AUTOSAR XML (schema 4-2-2)
package /AUTOSAR_Dcm/SwComponentTypes
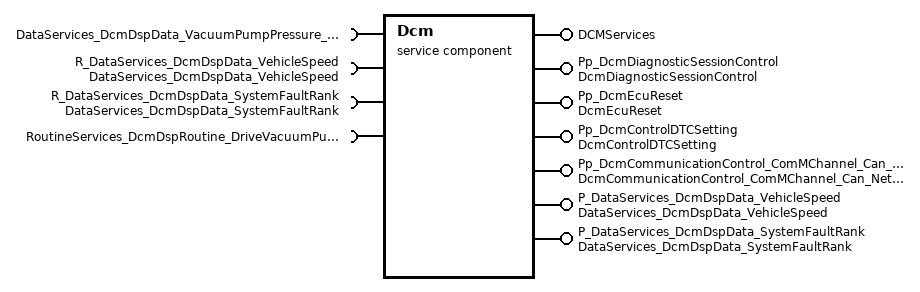
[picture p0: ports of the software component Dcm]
  service sw component type Dcm
    5 x provide port:
      DCMServices: provided-interface=DCMServices
      Pp_DcmDiagnosticSessionControl: mode-switch-sender-com-spec{mode-group=MDGP_DcmDiagnosticSessionControl, queue-length=1}, provided-interface=DcmDiagnosticSessionControl
      Pp_DcmEcuReset: mode-switch-sender-com-spec{mode-group=MDGP_DcmEcuReset, queue-length=1}, provided-interface=DcmEcuReset
      Pp_DcmControlDTCSetting: mode-switch-sender-com-spec{mode-group=MDGP_DcmControlDTCSetting, queue-length=1}, provided-interface=DcmControlDTCSetting
      Pp_DcmCommunicationControl_ComMChannel_Can_Network_Channel: mode-switch-sender-com-spec{mode-group=MDGP_DcmCommunicationControl_ComMChannel_Can_Network_Channel, queue-length=1}, provided-interface=DcmCommunicationControl_ComMChannel_Can_Network_Channel
    require port DataServices_DcmDspData_VacuumPumpPressure_1100: required-interface=DataServices_DcmDspData_VacuumPumpPressure_1100
    require port R_DataServices_DcmDspData_VehicleSpeed: required-interface=DataServices_DcmDspData_VehicleSpeed
    provide port P_DataServices_DcmDspData_VehicleSpeed: provided-interface=DataServices_DcmDspData_VehicleSpeed
    require port R_DataServices_DcmDspData_SystemFaultRank: required-interface=DataServices_DcmDspData_SystemFaultRank
    provide port P_DataServices_DcmDspData_SystemFaultRank: provided-interface=DataServices_DcmDspData_SystemFaultRank
    require port RoutineServices_DcmDspRoutine_DriveVacuumPump: required-interface=RoutineServices_DcmDspRoutine_DriveVacuumPump
    behavior IntBeh_Dcm: data-type-mapping=[DTS_DcmDiagnosticSessionControl, DTS_DcmEcuReset, DTS_DcmControlDTCSetting, DTS_DcmCommunicationControl_ComMChannel_Can_Network_Channel], included-data-type-set=data-type=[Dcm_SecLevelType, Dcm_SesCtrlType, Dcm_ProtocolType, Dcm_NegativeResponseCodeType, Dcm_ConfirmationStatusType, Dcm_OpStatusType, Dcm_DidSupportedType]
      5 x operation invoked event:
        OpInvEvent_DCMServices_GAP: start-on-event=Dcm_GetActiveProtocol, operation=DCMServices.GetActiveProtocol
        OpInvEvent_DCMServices_SAD: start-on-event=Dcm_SetActiveDiagnostic, operation=DCMServices.SetActiveDiagnostic
        OpInvEvent_DCMServices_GSCT: start-on-event=Dcm_GetSesCtrlType, operation=DCMServices.GetSesCtrlType
        OpInvEvent_DCMServices_GSL: start-on-event=Dcm_GetSecurityLevel, operation=DCMServices.GetSecurityLevel
        OpInvEvent_DCMServices_RD: start-on-event=Dcm_ResetToDefaultSession, operation=DCMServices.ResetToDefaultSession
      port-api-options:
        enable-take-address=true, indirect-api=false, port=DataServices_DcmDspData_VacuumPumpPressure_1100
        enable-take-address=true, indirect-api=false, port=RoutineServices_DcmDspRoutine_DriveVacuumPump
      6 x runnable:
        Dcm_MainFunction
          data-receive-point-by-arguments:
            access DcmDspData_VehicleSpeed_Read: accessed-variable=R_DataServices_DcmDspData_VehicleSpeed.Data
            access DcmDspData_SystemFaultRank_Read: accessed-variable=R_DataServices_DcmDspData_SystemFaultRank.Data
          data-send-points:
            access DcmDspData_VehicleSpeed_Write: accessed-variable=P_DataServices_DcmDspData_VehicleSpeed.Data
            access DcmDspData_SystemFaultRank_Write: accessed-variable=P_DataServices_DcmDspData_SystemFaultRank.Data
          4 x mode switch point:
            ModeSwitchPoint_0: mode-group=Pp_DcmDiagnosticSessionControl.MDGP_DcmDiagnosticSessionControl
            ModeSwitchPoint_1: mode-group=Pp_DcmEcuReset.MDGP_DcmEcuReset
            ModeSwitchPoint_3: mode-group=Pp_DcmControlDTCSetting.MDGP_DcmControlDTCSetting
            ModeSwitchPoint_ComMChannel_Can_Network_Channel: mode-group=Pp_DcmCommunicationControl_ComMChannel_Can_Network_Channel.MDGP_DcmCommunicationControl_ComMChannel_Can_Network_Channel
          8 x sync call, all with timeout=0.0:
            DataServices_DcmDspData_VacuumPumpPressure_1100_RData: operation=DataServices_DcmDspData_VacuumPumpPressure_1100.ReadData
            DataServices_DcmDspData_VacuumPumpPressure_1100_RCE: operation=DataServices_DcmDspData_VacuumPumpPressure_1100.ReturnControlToECU
            DataServices_DcmDspData_VacuumPumpPressure_1100_RD: operation=DataServices_DcmDspData_VacuumPumpPressure_1100.ResetToDefault
            DataServices_DcmDspData_VacuumPumpPressure_1100_STA: operation=DataServices_DcmDspData_VacuumPumpPressure_1100.ShortTermAdjustment
            DataServices_DcmDspData_VacuumPumpPressure_1100_FCS: operation=DataServices_DcmDspData_VacuumPumpPressure_1100.FreezeCurrentState
            SSC_Rout_DcmDspRoutine_DriveVacuumPump_Start: operation=RoutineServices_DcmDspRoutine_DriveVacuumPump.Start
            SSC_Rout_DcmDspRoutine_DriveVacuumPump_Stop: operation=RoutineServices_DcmDspRoutine_DriveVacuumPump.Stop
            SSC_Rout_DcmDspRoutine_DriveVacuumPump_ReqRes: operation=RoutineServices_DcmDspRoutine_DriveVacuumPump.RequestResults
        Dcm_GetActiveProtocol: can-be-invoked-concurrently=true
        Dcm_SetActiveDiagnostic: can-be-invoked-concurrently=true
        Dcm_GetSesCtrlType: can-be-invoked-concurrently=true
        Dcm_GetSecurityLevel: can-be-invoked-concurrently=true
        Dcm_ResetToDefaultSession: can-be-invoked-concurrently=true
package /AUTOSAR_Dcm/SwcImplementations
  swc implementation Impl_Dcm: programming-language=C, sw-version=42.5.0.0, swc-bsw-mapping=SwcBswMappings, vendor-id=6, behavior=IntBeh_Dcm
    code-descriptors:
      code CodeDescr_Dcm: artifact-descriptors=autosar-engineering-object={short-label=Code_0, category=SWSRC}
package /AUTOSAR_Dcm/CompuMethods
  compu method Dcm_RidSupportedType_Values: 0=DCM_RID_SUPPORTED_IN_RANGE, 1=DCM_RID_NOT_SUPPORTED
package /AUTOSAR_Dcm/ImplementationDataTypes
  21 x impl type:
    Dcm_SesCtrlType: compu {1=DCM_DEFAULT_SESSION, 2=DCM_PROGRAMMING_SESSION, 3=DCM_EXTENDED_DIAGNOSTIC_SESSION, 4=DCM_SAFETY_SYSTEM_DIAGNOSTIC_SESSION}, implementation-data-type=uint8
    Dcm_NegativeResponseCodeType: compu {17=DCM_E_SERVICENOTSUPPORTED, 18=DCM_E_SUBFUNCTIONNOTSUPPORTED, 19=DCM_E_INCORRECTMESSAGELENGTHORINVALIDFORMAT, 20=DCM_E_RESPONSETOOLONG, 53=DCM_E_INVALIDKEY, 54=DCM_E_EXCEEDNUMBEROFATTEMPTS, 55=DCM_E_REQUIREDTIMEDELAYNOTEXPIRED, 112=DCM_E_UPLOADDOWNLOADNOTACCEPTED, 113=DCM_E_TRANSFERDATASUSPENDED, 115=DCM_E_WRONGBLOCKSEQUENCECOUNTER, 127=DCM_E_SERVICENOTSUPPORTEDINACTIVESESSION, 140=DCM_E_TRANSMISSIONRANGENOTINNEUTRAL, 34=DCM_E_CONDITIONSNOTCORRECT, 16=DCM_E_GENERALREJECT, 33=DCM_E_BUSYREPEATREQUEST, 36=DCM_E_REQUESTSEQUENCEERROR, 37=DCM_E_NORESPONSEFROMSUBNETCOMPONENT, 38=DCM_E_FAILUREPREVENTSEXECUTIONOFREQUESTEDACTION, 49=DCM_E_REQUESTOUTOFRANGE, 51=DCM_E_SECURITYACCESSDENIED, 114=DCM_E_GENERALPROGRAMMINGFAILURE, 126=DCM_E_SUBFUNCTIONNOTSUPPORTEDINACTIVESESSION, 129=DCM_E_RPMTOOHIGH, 130=DCM_E_RPMTOOLOW, 131=DCM_E_ENGINEISRUNNING, 132=DCM_E_ENGINEISNOTRUNNING, 133=DCM_E_ENGINERUNTIMETOOLOW, 134=DCM_E_TEMPERATURETOOHIGH, 135=DCM_E_TEMPERATURETOOLOW, 136=DCM_E_VEHICLESPEEDTOOHIGH, 137=DCM_E_VEHICLESPEEDTOOLOW, 138=DCM_E_THROTTLE_PEDALTOOHIGH, 139=DCM_E_THROTTLE_PEDALTOOLOW, 141=DCM_E_TRANSMISSIONRANGENOTINGEAR, 146=DCM_E_VOLTAGETOOHIGH, 143=DCM_E_BRAKESWITCH_NOTCLOSED, 144=DCM_E_SHIFTERLEVERNOTINPARK, 145=DCM_E_TORQUECONVERTERCLUTCHLOCKED, 147=DCM_E_VOLTAGETOOLOW}, implementation-data-type=uint8
    Dcm_InputOutputControlParameterType: compu {255=DCM_IDLE, 3=DCM_SHORT_TERM_ADJUSTMENT, 2=DCM_FREEZE_CURRENT_STATE, 1=DCM_RESET_TO_DEFAULT, 0=DCM_RETURN_CONTROL_TO_ECU}, implementation-data-type=uint8
    Dcm_IOOperationResponseType: compu {255=DCM_IDLE, 0=DCM_POSITIVE_RESPONSE, 16=DCM_GENERAL_REJECT, 33=DCM_BUSY_REPEAT_REQUEST, 34=DCM_CONDITIONS_NOT_CORRECT, 38=DCM_FAILURE_PREVENTS_EXECUTION, 49=DCM_REQUEST_OUT_OF_RANGE, 120=DCM_RESPONSE_PENDING}, implementation-data-type=uint8
    Dcm_IOControlResponseType: category=STRUCTURE
      element IOOperationResponse: implementation-data-type=Dcm_IOOperationResponseType
    Dcm_DataArrayTypeUint8_DcmDspData_VacuumPumpPressure_1100Type: category=ARRAY
      element DataArray: array-size=2, array-size-semantics=FIXED-SIZE, implementation-data-type=uint8
    Dcm_DataArrayTypeUint8_DcmDspData_VehicleSpeedType: implementation-data-type=uint8
    Dcm_DataArrayTypeUint8_DcmDspData_SystemFaultRankType: implementation-data-type=uint8
    Dcm_ConfirmationStatusType: compu {0=DCM_RES_POS_OK, 1=DCM_RES_POS_NOT_OK, 2=DCM_RES_NEG_OK, 3=DCM_RES_NEG_NOT_OK}, implementation-data-type=uint8
    Dcm_ProtocolType: compu {0=DCM_OBD_ON_CAN, 1=DCM_OBD_ON_FLEXRAY, 2=DCM_OBD_ON_IP, 3=DCM_UDS_ON_CAN, 4=DCM_UDS_ON_FLEXRAY, 5=DCM_UDS_ON_IP, 6=DCM_ROE_ON_CAN, 7=DCM_ROE_ON_FLEXRAY, 8=DCM_ROE_ON_IP, 9=DCM_PERIODICTRANS_ON_CAN, 10=DCM_PERIODICTRANS_ON_FLEXRAY, 11=DCM_PERIODICTRANS_ON_IP, 12=DCM_NO_ACTIVE_PROTOCOL, 144=DCM_ACEA_ON_CAN, 145=DCM_ACEA_ON_FLEXRAY, 128=DCM_KWP_ON_KLINE, 129=DCM_KWP_ON_CAN, 160=DCM_CARB_ON_KLINE, 161=DCM_OBD_ON_KLINE, 240..254=DCM_SUPPLIER_1..DCM_SUPPLIER_15}, implementation-data-type=uint8
    Dcm_SecLevelType: compu {1=DCM_SEC_LEV_L1}, implementation-data-type=uint8
    Dcm_StartDataIn_DcmDspRoutine_DriveVacuumPump_DcmDspStartRoutineInSignalType: implementation-data-type=Dcm_StartDataIn_DcmDspRoutine_DriveVacuumPump_DcmDspStartRoutineInSignalPrimitivType
    Dcm_StartDataIn_DcmDspRoutine_DriveVacuumPump_DcmDspStartRoutineInSignalPrimitivType: implementation-data-type=uint8
    Dcm_StartDataOut_DcmDspRoutine_DriveVacuumPump_DcmDspStartRoutineOutSignalType: implementation-data-type=Dcm_StartDataOut_DcmDspRoutine_DriveVacuumPump_DcmDspStartRoutineOutSignalPrimitivType
    Dcm_StartDataOut_DcmDspRoutine_DriveVacuumPump_DcmDspStartRoutineOutSignalPrimitivType: implementation-data-type=uint8
    Dcm_StopDataOut_DcmDspRoutine_DriveVacuumPump_DcmDspStopRoutineOutSignalType: implementation-data-type=Dcm_StopDataOut_DcmDspRoutine_DriveVacuumPump_DcmDspStopRoutineOutSignalPrimitivType
    Dcm_StopDataOut_DcmDspRoutine_DriveVacuumPump_DcmDspStopRoutineOutSignalPrimitivType: implementation-data-type=uint8
    Dcm_RequestDataOut_DcmDspRoutine_DriveVacuumPump_DcmDspRequestRoutineResultsOutSignal_0Type: implementation-data-type=Dcm_RequestDataOut_DcmDspRoutine_DriveVacuumPump_DcmDspRequestRoutineResultsOutSignal_0PrimitivType
    Dcm_RequestDataOut_DcmDspRoutine_DriveVacuumPump_DcmDspRequestRoutineResultsOutSignal_0PrimitivType: implementation-data-type=uint8
    Dcm_OpStatusType: compu {0=DCM_INITIAL, 1=DCM_PENDING, 2=DCM_CANCEL, 3=DCM_FORCE_RCRRP_OK}, implementation-data-type=uint8
    Dcm_DidSupportedType: compu {0=DCM_DID_SUPPORTED, 1=DCM_DID_NOT_SUPPORTED}, implementation-data-type=uint8
package /AUTOSAR_Dcm/DataTypeMappingSets
  4 x data type mapping set:
    DTS_DcmDiagnosticSessionControl: mode-request-type-map{implementation-data-type=uint8, mode-group=DcmDiagnosticSessionControl}
    DTS_DcmEcuReset: mode-request-type-map{implementation-data-type=uint8, mode-group=DcmEcuReset}
    DTS_DcmControlDTCSetting: mode-request-type-map{implementation-data-type=uint8, mode-group=DcmControlDTCSetting}
    DTS_DcmCommunicationControl_ComMChannel_Can_Network_Channel: mode-request-type-map{implementation-data-type=uint8, mode-group=DcmCommunicationControl_ComMChannel_Can_Network_Channel}
package /AUTOSAR_Dcm/SwcBswMappings
  swc bsw mapping SwcBswMappings: bsw-behavior=BswInternalBehavior, swc-bsw-runnable-mapping{bsw-entity=BSWSE_DcmMainFunction, swc-runnable=Dcm_MainFunction}, swc-behavior=IntBeh_Dcm
    synchronized-mode-groups:
      bsw-mode-group=DcmDiagnosticSessionControl, swc-mode-group=Pp_DcmDiagnosticSessionControl.MDGP_DcmDiagnosticSessionControl
      bsw-mode-group=DcmEcuReset, swc-mode-group=Pp_DcmEcuReset.MDGP_DcmEcuReset
      bsw-mode-group=DcmControlDTCSetting, swc-mode-group=Pp_DcmControlDTCSetting.MDGP_DcmControlDTCSetting
      bsw-mode-group=DcmCommunicationControl_ComMChannel_Can_Network_Channel, swc-mode-group=Pp_DcmCommunicationControl_ComMChannel_Can_Network_Channel.MDGP_DcmCommunicationControl_ComMChannel_Can_Network_Channel
package /AUTOSAR_Dcm/PortInterfaces
  client server interface DataServices_DcmDspData_VacuumPumpPressure_1100: is-service=true
    5 x operation, all with possible-error=[DataServices_DcmDspData_VacuumPumpPressure_1100/E_OK, DataServices_DcmDspData_VacuumPumpPressure_1100/E_NOT_OK]:
      ReadData
        arg Data: type=Dcm_DataArrayTypeUint8_DcmDspData_VacuumPumpPressure_1100Type, direction=OUT
      ReturnControlToECU
        arg ErrorCode: type=Dcm_NegativeResponseCodeType, direction=OUT
      ResetToDefault
        arg ErrorCode: type=Dcm_NegativeResponseCodeType, direction=OUT
      FreezeCurrentState
        arg ErrorCode: type=Dcm_NegativeResponseCodeType, direction=OUT
      ShortTermAdjustment
        arg ControlStateInfo: type=Dcm_DataArrayTypeUint8_DcmDspData_VacuumPumpPressure_1100Type, direction=IN
        arg ErrorCode: type=Dcm_NegativeResponseCodeType, direction=OUT
    error E_OK: error-code=0
    error E_NOT_OK: error-code=1
  sender receiver interface DataServices_DcmDspData_VehicleSpeed
    data Data: type=Dcm_DataArrayTypeUint8_DcmDspData_VehicleSpeedType
  sender receiver interface DataServices_DcmDspData_SystemFaultRank
    data Data: type=Dcm_DataArrayTypeUint8_DcmDspData_SystemFaultRankType
  client server interface DCMServices: is-service=true
    5 x operation:
      GetActiveProtocol: possible-error=[DCMServices/E_OK, DCMServices/E_NOT_OK]
        arg ActiveProtocol: type=Dcm_ProtocolType, direction=OUT
      SetActiveDiagnostic: possible-error=DCMServices/E_OK
        arg active: type=boolean, direction=IN
      GetSesCtrlType: possible-error=[DCMServices/E_OK, DCMServices/E_NOT_OK]
        arg SesCtrlType: type=Dcm_SesCtrlType, direction=OUT
      GetSecurityLevel: possible-error=[DCMServices/E_OK, DCMServices/E_NOT_OK]
        arg SecLevel: type=Dcm_SecLevelType, direction=OUT
      ResetToDefaultSession: possible-error=[DCMServices/E_OK, DCMServices/E_NOT_OK]
    error E_OK: error-code=0
    error E_NOT_OK: error-code=1
  client server interface RoutineServices_DcmDspRoutine_DriveVacuumPump: is-service=true
    operation Start: possible-error=[RoutineServices_DcmDspRoutine_DriveVacuumPump/E_OK, RoutineServices_DcmDspRoutine_DriveVacuumPump/E_NOT_OK, DCM_E_PENDING, DCM_E_FORCE_RCRRP]
      4 x arg:
        DataIn_DcmDspStartRoutineInSignal: type=Dcm_StartDataIn_DcmDspRoutine_DriveVacuumPump_DcmDspStartRoutineInSignalType, direction=IN
        OpStatus: type=Dcm_OpStatusType, direction=IN
        DataOut_DcmDspStartRoutineOutSignal: type=Dcm_StartDataOut_DcmDspRoutine_DriveVacuumPump_DcmDspStartRoutineOutSignalType, direction=OUT
        ErrorCode: type=Dcm_NegativeResponseCodeType, direction=OUT
    operation Stop: possible-error=[RoutineServices_DcmDspRoutine_DriveVacuumPump/E_OK, RoutineServices_DcmDspRoutine_DriveVacuumPump/E_NOT_OK, DCM_E_PENDING, DCM_E_FORCE_RCRRP]
      arg OpStatus: type=Dcm_OpStatusType, direction=IN
      arg DataOut_DcmDspStopRoutineOutSignal: type=Dcm_StopDataOut_DcmDspRoutine_DriveVacuumPump_DcmDspStopRoutineOutSignalType, direction=OUT
      arg ErrorCode: type=Dcm_NegativeResponseCodeType, direction=OUT
    operation RequestResults: possible-error=[RoutineServices_DcmDspRoutine_DriveVacuumPump/E_OK, RoutineServices_DcmDspRoutine_DriveVacuumPump/E_NOT_OK, DCM_E_PENDING, DCM_E_FORCE_RCRRP]
      arg OpStatus: type=Dcm_OpStatusType, direction=IN
      arg DataOut_DcmDspRequestRoutineResultsOutSignal_0: type=Dcm_RequestDataOut_DcmDspRoutine_DriveVacuumPump_DcmDspRequestRoutineResultsOutSignal_0Type, direction=OUT
      arg ErrorCode: type=Dcm_NegativeResponseCodeType, direction=OUT
    4 x error:
      E_OK: error-code=0
      E_NOT_OK: error-code=1
      DCM_E_PENDING: error-code=10
      DCM_E_FORCE_RCRRP: error-code=12
  4 x mode switch interface, all with is-service=true:
    DcmDiagnosticSessionControl
      mode group MDGP_DcmDiagnosticSessionControl: type=DcmDiagnosticSessionControl
    DcmEcuReset
      mode group MDGP_DcmEcuReset: type=DcmEcuReset
    DcmControlDTCSetting
      mode group MDGP_DcmControlDTCSetting: type=DcmControlDTCSetting
    DcmCommunicationControl_ComMChannel_Can_Network_Channel
      mode group MDGP_DcmCommunicationControl_ComMChannel_Can_Network_Channel: type=DcmCommunicationControl_ComMChannel_Can_Network_Channel
